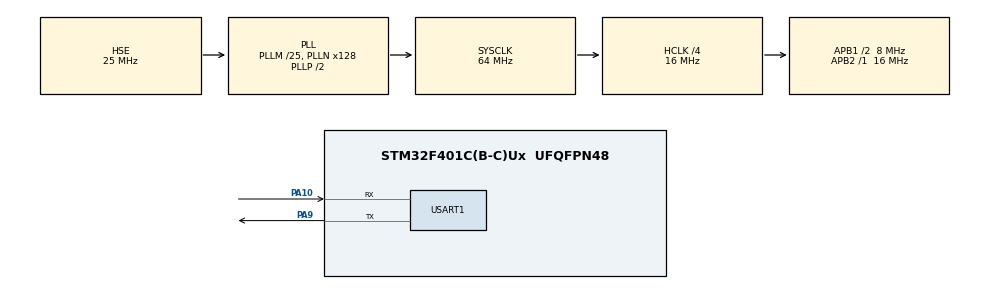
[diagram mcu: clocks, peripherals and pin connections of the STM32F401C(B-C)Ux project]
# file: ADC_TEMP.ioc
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ADC1.Channel-0\#ChannelRegularConversion=ADC_CHANNEL_TEMPSENSOR
ADC1.ContinuousConvMode=DISABLE
ADC1.DMAContinuousRequests=ENABLE
ADC1.EOCSelection=ADC_EOC_SEQ_CONV
ADC1.ExternalTrigConv=ADC_EXTERNALTRIGCONV_T2_TRGO
ADC1.NbrOfConversionFlag=1
ADC1.Rank-0\#ChannelRegularConversion=1
ADC1.SamplingTime-0\#ChannelRegularConversion=ADC_SAMPLETIME_144CYCLES
ADC1.master=1
Dma.ADC1.0.Direction=DMA_PERIPH_TO_MEMORY
Dma.ADC1.0.FIFOMode=DMA_FIFOMODE_DISABLE
Dma.ADC1.0.Instance=DMA2_Stream0
Dma.ADC1.0.MemDataAlignment=DMA_MDATAALIGN_HALFWORD
Dma.ADC1.0.MemInc=DMA_MINC_ENABLE
Dma.ADC1.0.Mode=DMA_CIRCULAR
Dma.ADC1.0.PeriphDataAlignment=DMA_PDATAALIGN_HALFWORD
Dma.ADC1.0.PeriphInc=DMA_PINC_DISABLE
Dma.ADC1.0.Priority=DMA_PRIORITY_LOW
Dma.Request0=ADC1
Mcu.Family=STM32F4
Mcu.Name=STM32F401C(B-C)Ux
Mcu.Package=UFQFPN48
NVIC.DMA2_Stream0_IRQn=true\:0\:0\:false\:false\:true\:false\:true
NVIC.PriorityGroup=NVIC_PRIORITYGROUP_4
PA10.Mode=Asynchronous
PA10.Signal=USART1_RX
PA13.Mode=Serial_Wire
PA13.Signal=SYS_JTMS-SWDIO
PA14.Mode=Serial_Wire
PA14.Signal=SYS_JTCK-SWCLK
PA9.Mode=Asynchronous
PA9.Signal=USART1_TX
PH0\ -\ OSC_IN.Mode=HSE-External-Oscillator
PH0\ -\ OSC_IN.Signal=RCC_OSC_IN
PH1\ -\ OSC_OUT.Mode=HSE-External-Oscillator
PH1\ -\ OSC_OUT.Signal=RCC_OSC_OUT
ProjectManager.HeapSize=0x200
ProjectManager.StackSize=0x400
ProjectManager.TargetToolchain=STM32CubeIDE
RCC.48MHZClocksFreq_Value=32000000
RCC.AHBCLKDivider=RCC_SYSCLK_DIV4
RCC.AHBFreq_Value=16000000
RCC.APB1CLKDivider=RCC_HCLK_DIV2
RCC.APB1Freq_Value=8000000
RCC.APB1TimFreq_Value=16000000
RCC.APB2Freq_Value=16000000
RCC.APB2TimFreq_Value=16000000
RCC.CortexFreq_Value=16000000
RCC.HCLKFreq_Value=16000000
RCC.HSE_VALUE=25000000
RCC.HSI_VALUE=16000000
RCC.LSE_VALUE=32768
RCC.PLLM=25
RCC.PLLN=128
RCC.PLLSourceVirtual=RCC_PLLSOURCE_HSE
RCC.SYSCLKFreq_VALUE=64000000
RCC.SYSCLKSource=RCC_SYSCLKSOURCE_PLLCLK
RCC.VCOOutputFreq_Value=128000000
TIM2.Period=1000-1
TIM2.Prescaler=16000-1
TIM2.TIM_MasterOutputTrigger=TIM_TRGO_UPDATE
TIM2.TIM_MasterSlaveMode=TIM_MASTERSLAVEMODE_ENABLE
USART1.VirtualMode=VM_ASYNC
VP_ADC1_TempSens_Input.Mode=IN-TempSens
VP_TIM2_VS_ClockSourceINT.Mode=Internal
board=custom

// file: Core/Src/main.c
/* USER CODE BEGIN Header */
/**
  ******************************************************************************
  * @file           : main.c
  * @brief          : Main program body
  ******************************************************************************
  * @attention
  *
  * <h2><center>&copy; Copyright (c) 2021 STMicroelectronics.
  * All rights reserved.</center></h2>
  *
  * This software component is licensed by ST under BSD 3-Clause license,
  * the "License"; You may not use this file except in compliance with the
  * License. You may obtain a copy of the License at:
  *                        opensource.org/licenses/BSD-3-Clause
  *
  ******************************************************************************
  */
/* USER CODE END Header */
#include "main.h"

/* USER CODE BEGIN Includes */
#include <stdio.h>
/* USER CODE END Includes */

ADC_HandleTypeDef hadc1;
DMA_HandleTypeDef hdma_adc1;

TIM_HandleTypeDef htim2;

UART_HandleTypeDef huart1;

/* USER CODE BEGIN PV */
float voltage = 0.0;
float tempDegC = 0.0;
uint16_t adcValue = 0;
__IO uint8_t isConversionDone = 0;   // used in interrupt callback
char msg[30] = {0};
/* USER CODE END PV */

void SystemClock_Config(void);
static void MX_GPIO_Init(void);
static void MX_ADC1_Init(void);
static void MX_DMA_Init(void);
static void MX_TIM2_Init(void);
static void MX_USART1_UART_Init(void);

int main(void)
{

  /* MCU Configuration--------------------------------------------------------*/

  /* Reset of all peripherals, Initializes the Flash interface and the Systick. */
  HAL_Init();

  /* Configure the system clock */
  SystemClock_Config();

  /* Initialize all configured peripherals */
  MX_GPIO_Init();
  MX_ADC1_Init();
  MX_DMA_Init();
  MX_TIM2_Init();
  MX_USART1_UART_Init();
  /* USER CODE BEGIN 2 */
  if (HAL_ADC_Start_DMA(&hadc1, (uint32_t*) &adcValue, 1) != HAL_OK)
	  Error_Handler();
  if(HAL_TIM_Base_Start(&htim2) != HAL_OK)
	  Error_Handler();
  /* USER CODE END 2 */

  /* Infinite loop */
  while (1)
  {

    /* USER CODE BEGIN 3 */

	/* Computation of ADC conversions raw data to physical values             */
	if (isConversionDone == 1) {
		isConversionDone = 0;
		voltage = (float) adcValue / 4095 * 3300;  // mV
		tempDegC = (voltage - 760.0) / 2.5 + 25;
		sprintf(msg, "Temperature = %.1f C\n\r", tempDegC);
		HAL_UART_Transmit(&huart1, (uint8_t*) msg, sizeof(msg),	HAL_MAX_DELAY);
	}
  }
  /* USER CODE END 3 */
}

void SystemClock_Config(void)
{
  RCC_OscInitTypeDef RCC_OscInitStruct = {0};
  RCC_ClkInitTypeDef RCC_ClkInitStruct = {0};

  /** Configure the main internal regulator output voltage
  */
  __HAL_RCC_PWR_CLK_ENABLE();
  __HAL_PWR_VOLTAGESCALING_CONFIG(PWR_REGULATOR_VOLTAGE_SCALE2);
  /** Initializes the RCC Oscillators according to the specified parameters
  * in the RCC_OscInitTypeDef structure.
  */
  RCC_OscInitStruct.OscillatorType = RCC_OSCILLATORTYPE_HSE;
  RCC_OscInitStruct.HSEState = RCC_HSE_ON;
  RCC_OscInitStruct.PLL.PLLState = RCC_PLL_ON;
  RCC_OscInitStruct.PLL.PLLSource = RCC_PLLSOURCE_HSE;
  RCC_OscInitStruct.PLL.PLLM = 25;
  RCC_OscInitStruct.PLL.PLLN = 128;
  RCC_OscInitStruct.PLL.PLLP = RCC_PLLP_DIV2;
  RCC_OscInitStruct.PLL.PLLQ = 4;
  if (HAL_RCC_OscConfig(&RCC_OscInitStruct) != HAL_OK)
  {
    Error_Handler();
  }
  /** Initializes the CPU, AHB and APB buses clocks
  */
  RCC_ClkInitStruct.ClockType = RCC_CLOCKTYPE_HCLK|RCC_CLOCKTYPE_SYSCLK
                              |RCC_CLOCKTYPE_PCLK1|RCC_CLOCKTYPE_PCLK2;
  RCC_ClkInitStruct.SYSCLKSource = RCC_SYSCLKSOURCE_PLLCLK;
  RCC_ClkInitStruct.AHBCLKDivider = RCC_SYSCLK_DIV4;
  RCC_ClkInitStruct.APB1CLKDivider = RCC_HCLK_DIV2;
  RCC_ClkInitStruct.APB2CLKDivider = RCC_HCLK_DIV1;

  if (HAL_RCC_ClockConfig(&RCC_ClkInitStruct, FLASH_LATENCY_0) != HAL_OK)
  {
    Error_Handler();
  }
}

static void MX_ADC1_Init(void)
{

  ADC_ChannelConfTypeDef sConfig = {0};

  /** Configure the global features of the ADC (Clock, Resolution, Data Alignment and number of conversion)
  */
  hadc1.Instance = ADC1;
  hadc1.Init.ClockPrescaler = ADC_CLOCK_SYNC_PCLK_DIV2;
  hadc1.Init.Resolution = ADC_RESOLUTION_12B;
  hadc1.Init.ScanConvMode = DISABLE;
  hadc1.Init.ContinuousConvMode = DISABLE;
  hadc1.Init.DiscontinuousConvMode = DISABLE;
  hadc1.Init.ExternalTrigConvEdge = ADC_EXTERNALTRIGCONVEDGE_RISING;
  hadc1.Init.ExternalTrigConv = ADC_EXTERNALTRIGCONV_T2_TRGO;
  hadc1.Init.DataAlign = ADC_DATAALIGN_RIGHT;
  hadc1.Init.NbrOfConversion = 1;
  hadc1.Init.DMAContinuousRequests = ENABLE;
  hadc1.Init.EOCSelection = ADC_EOC_SEQ_CONV;
  if (HAL_ADC_Init(&hadc1) != HAL_OK)
  {
    Error_Handler();
  }
  /** Configure for the selected ADC regular channel its corresponding rank in the sequencer and its sample time.
  */
  sConfig.Channel = ADC_CHANNEL_TEMPSENSOR;
  sConfig.Rank = 1;
  sConfig.SamplingTime = ADC_SAMPLETIME_144CYCLES;
  if (HAL_ADC_ConfigChannel(&hadc1, &sConfig) != HAL_OK)
  {
    Error_Handler();
  }

}

static void MX_TIM2_Init(void)
{

  TIM_ClockConfigTypeDef sClockSourceConfig = {0};
  TIM_MasterConfigTypeDef sMasterConfig = {0};

  htim2.Instance = TIM2;
  htim2.Init.Prescaler = 16000-1;
  htim2.Init.CounterMode = TIM_COUNTERMODE_UP;
  htim2.Init.Period = 1000-1;
  htim2.Init.ClockDivision = TIM_CLOCKDIVISION_DIV1;
  htim2.Init.AutoReloadPreload = TIM_AUTORELOAD_PRELOAD_DISABLE;
  if (HAL_TIM_Base_Init(&htim2) != HAL_OK)
  {
    Error_Handler();
  }
  sClockSourceConfig.ClockSource = TIM_CLOCKSOURCE_INTERNAL;
  if (HAL_TIM_ConfigClockSource(&htim2, &sClockSourceConfig) != HAL_OK)
  {
    Error_Handler();
  }
  sMasterConfig.MasterOutputTrigger = TIM_TRGO_UPDATE;
  sMasterConfig.MasterSlaveMode = TIM_MASTERSLAVEMODE_ENABLE;
  if (HAL_TIMEx_MasterConfigSynchronization(&htim2, &sMasterConfig) != HAL_OK)
  {
    Error_Handler();
  }

}

static void MX_USART1_UART_Init(void)
{

  huart1.Instance = USART1;
  huart1.Init.BaudRate = 115200;
  huart1.Init.WordLength = UART_WORDLENGTH_8B;
  huart1.Init.StopBits = UART_STOPBITS_1;
  huart1.Init.Parity = UART_PARITY_NONE;
  huart1.Init.Mode = UART_MODE_TX_RX;
  huart1.Init.HwFlowCtl = UART_HWCONTROL_NONE;
  huart1.Init.OverSampling = UART_OVERSAMPLING_16;
  if (HAL_UART_Init(&huart1) != HAL_OK)
  {
    Error_Handler();
  }

}

static void MX_DMA_Init(void)
{

  /* DMA controller clock enable */
  __HAL_RCC_DMA2_CLK_ENABLE();

  /* DMA interrupt init */
  /* DMA2_Stream0_IRQn interrupt configuration */
  HAL_NVIC_SetPriority(DMA2_Stream0_IRQn, 0, 0);
  HAL_NVIC_EnableIRQ(DMA2_Stream0_IRQn);

}

static void MX_GPIO_Init(void)
{

  /* GPIO Ports Clock Enable */
  __HAL_RCC_GPIOH_CLK_ENABLE();
  __HAL_RCC_GPIOA_CLK_ENABLE();

}

/* USER CODE BEGIN 4 */
void HAL_ADC_ConvCpltCallback(ADC_HandleTypeDef* hadc) {
	if (hadc->Instance == ADC1)
		isConversionDone = 1;
}
/* USER CODE END 4 */

void Error_Handler(void)
{
  __disable_irq();
  while (1)
  {
  }
}

/************************ (C) COPYRIGHT STMicroelectronics *****END OF FILE****/
